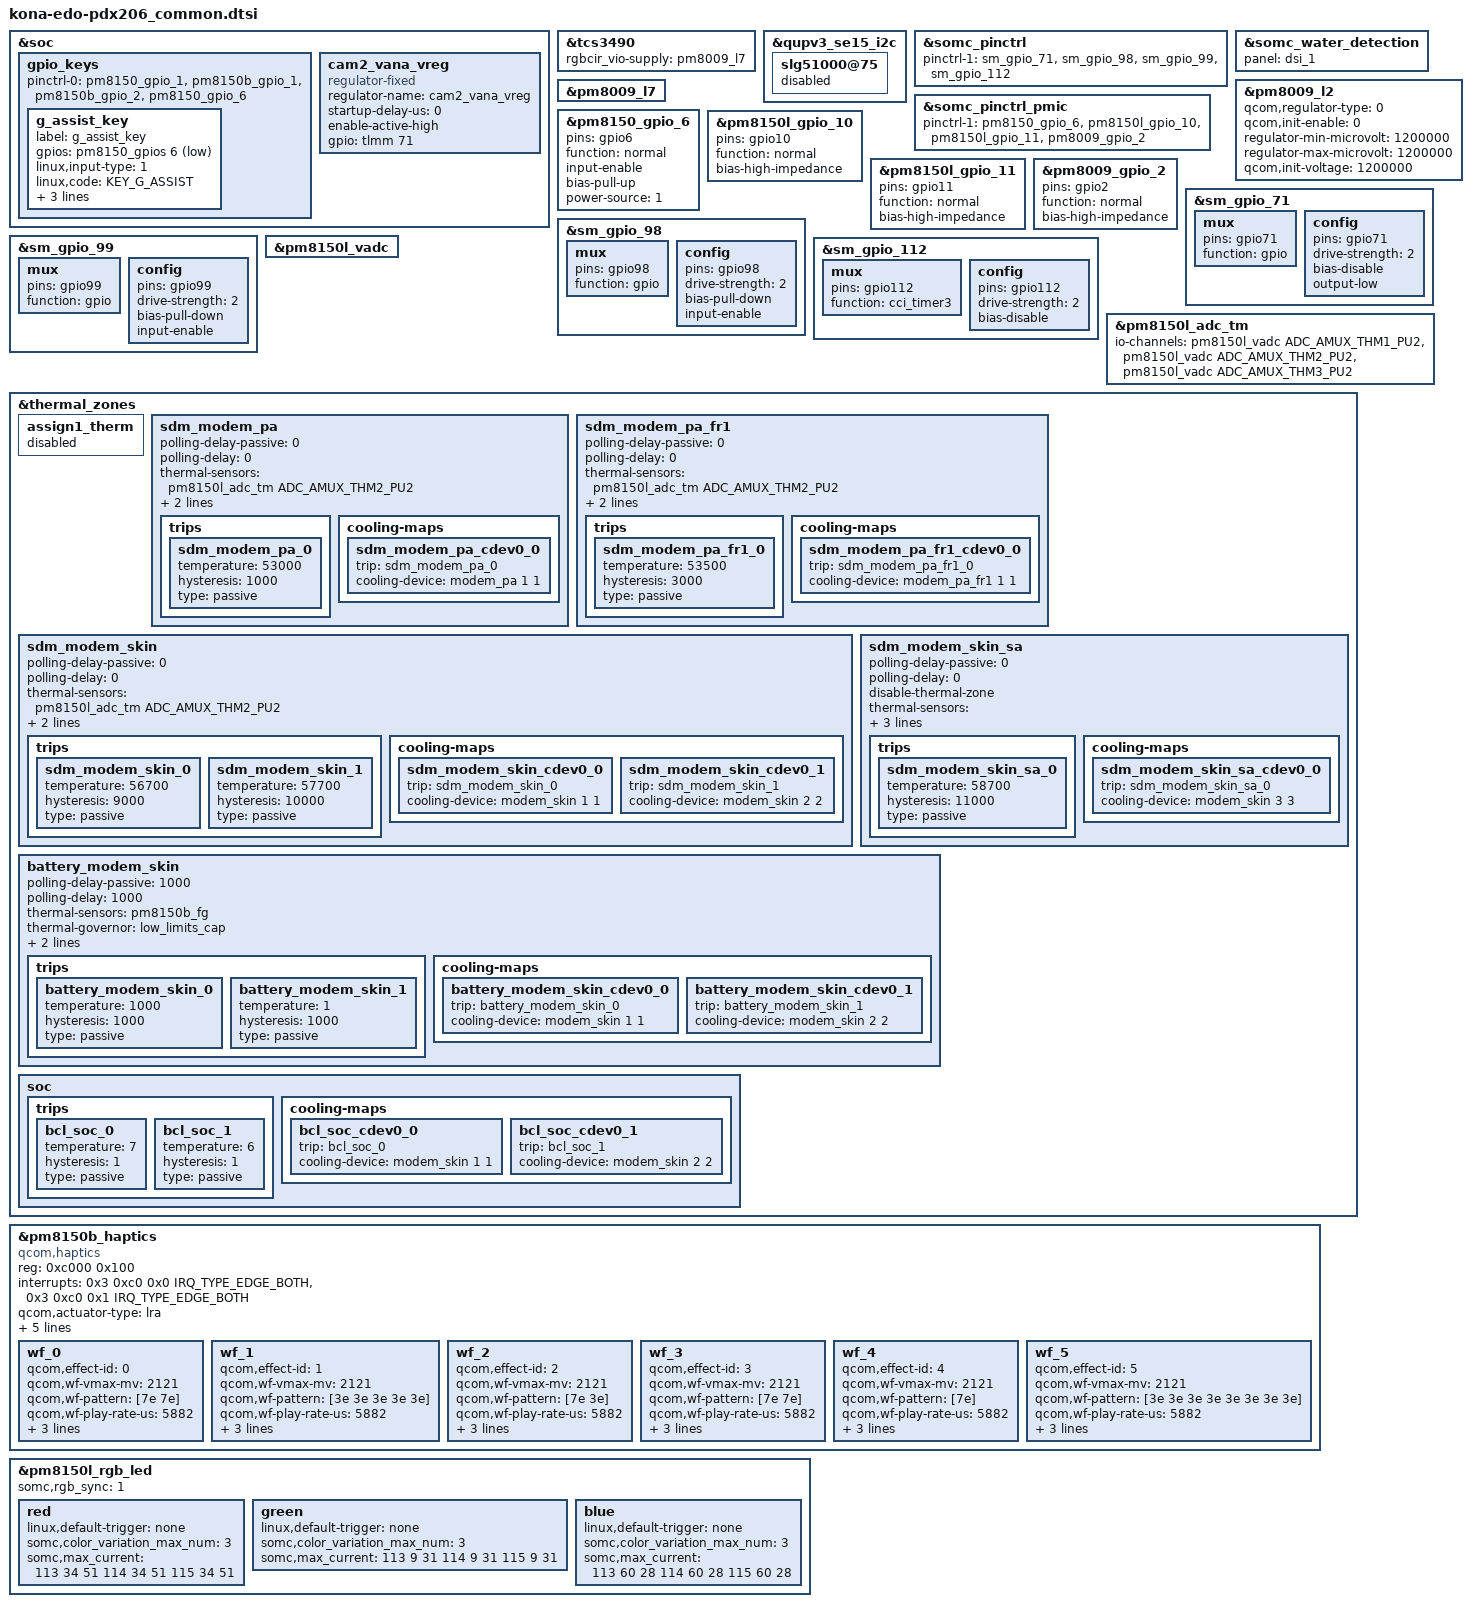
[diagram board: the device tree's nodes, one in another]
/* arch/arm64/boot/dts/vendor/somc/kona-edo-pdx206_common.dtsi
 *
 * This program is free software; you can redistribute it and/or modify
 * it under the terms of the GNU General Public License version 2 and
 * only version 2 as published by the Free Software Foundation.
 *
 * This program is distributed in the hope that it will be useful,
 * but WITHOUT ANY WARRANTY; without even the implied warranty of
 * MERCHANTABILITY or FITNESS FOR A PARTICULAR PURPOSE.  See the
 * GNU General Public License for more details.
 */

#include "kona-edo-common.dtsi"

&soc {
	gpio_keys {
		pinctrl-0 = <&pm8150_gpio_1
			     &pm8150b_gpio_1
			     &pm8150b_gpio_2
			     &pm8150_gpio_6>;
		g_assist_key {
			label = "g_assist_key";
			gpios = <&pm8150_gpios 6 GPIO_ACTIVE_LOW>;
			linux,input-type = <1>;
			linux,code = <KEY_G_ASSIST>;
			gpio-key,wakeup;
			debounce-interval = <15>;
			linux,can-disable;
		};
	};

	cam2_vana_vreg: cam2_vana_vreg {
		compatible = "regulator-fixed";
		regulator-name = "cam2_vana_vreg";
		startup-delay-us = <0>;
		enable-active-high;
		gpio = <&tlmm 71 0>;
	};
};

&tcs3490 {
	rgbcir_vio-supply = <&pm8009_l7>;
	/delete-property/ pmic_cs-supply;
};

&qupv3_se15_i2c {
	slg51000@75 {
		status = "disabled";
	};
};

&somc_pinctrl {
	/* If product common default setting is needed,
	fill pinctrl-1 value in <product>_common.dtsi */
	pinctrl-1 = <&sm_gpio_71 &sm_gpio_98 &sm_gpio_99 &sm_gpio_112>;
};

&somc_pinctrl_pmic {
	/* If product common PMIC default setting is needed,
	fill pinctrl-1 value in <product>_common.dtsi */
	pinctrl-1 = <&pm8150_gpio_6 &pm8150l_gpio_10 &pm8150l_gpio_11 &pm8009_gpio_2>;
};

&somc_water_detection {
	panel = <&dsi_1>;
};

/* Regulator config */
&pm8009_l2 {
	qcom,regulator-type = <0>;      /* LDO */
	qcom,init-enable = <0>;
	regulator-min-microvolt = <1200000>;
	regulator-max-microvolt = <1200000>;
	qcom,init-voltage = <1200000>;
	status = "okay";
};

&pm8009_l7 {
	status = "okay";
};

/* GPIO_6: G_ASSIST_N */
&pm8150_gpio_6 {
	pins = "gpio6";
	function = "normal";
	/delete-property/ bias-high-impedance;
	input-enable;
	bias-pull-up;
	power-source = <1>;
};

/* GPIO_10: NC */
&pm8150l_gpio_10 {
	pins = "gpio10";
	function = "normal";
	bias-high-impedance; /* DISABLE GPIO_10 */
};

/* GPIO_11: NC */
&pm8150l_gpio_11 {
	pins = "gpio11";
	function = "normal";
	/delete-property/ output-low;
	/delete-property/ drive-push-pull;
	/delete-property/ qcom,drive-strength;
	/delete-property/ power-source;
	bias-high-impedance; /* DISABLE GPIO_11 */
};

/* GPIO_2: NC */
&pm8009_gpio_2 {
	pins = "gpio2";
	function = "normal";
	/delete-property/ output-low;
	/delete-property/ drive-push-pull;
	/delete-property/ qcom,drive-strength;
	/delete-property/ power-source;
	bias-high-impedance; /* DISABLE GPIO_2 */
};

/* GPIO_71 : FRONTC_PWR_EN */
&sm_gpio_71 {
	mux {
		pins = "gpio71";
		function = "gpio";
	};

	config {
		pins = "gpio71";
		drive-strength = <2>;
		bias-disable;
		output-low;
	};
};

/* GPIO_98 : NC */
&sm_gpio_98 {
	mux {
		pins = "gpio98";
		function = "gpio";
	};

	config {
		pins = "gpio98";
		drive-strength = <2>;
		/delete-property/ bias-disable;
		bias-pull-down;
		input-enable;
	};
};

/* GPIO_99 : NC */
&sm_gpio_99 {
	mux {
		pins = "gpio99";
		function = "gpio";
	};

	config {
		pins = "gpio99";
		drive-strength = <2>;
		/delete-property/ bias-disable;
		bias-pull-down;
		/delete-property/ output-low;
		input-enable;
	};
};

/* GPIO_112 : XVS */
&sm_gpio_112 {
	mux {
		pins = "gpio112";
		function = "cci_timer3";
	};

	config {
		pins = "gpio112";
		drive-strength = <2>;
		/delete-property/ bias-pull-down;
		bias-disable;
		/delete-property/ input-enable;
	};
};

&pm8150l_vadc {
	/delete-node/ assign1_therm@55;
};

&pm8150l_adc_tm {
	io-channels = <&pm8150l_vadc ADC_AMUX_THM1_PU2>,
			<&pm8150l_vadc ADC_AMUX_THM2_PU2>,
			<&pm8150l_vadc ADC_AMUX_THM3_PU2>;

	/delete-node/ assign1_therm@55;
};

&thermal_zones {
	assign1_therm {
		status = "disable";
	};

	sdm_modem_pa {
		polling-delay-passive = <0>;
		polling-delay = <0>;
		thermal-sensors = <&pm8150l_adc_tm ADC_AMUX_THM2_PU2>;
		thermal-governor = "step_wise";
		wake-capable-sensor;
		trips {
			sdm_modem_pa_0: sdm_modem_pa_0 {
				temperature = <53000>;
				hysteresis = <1000>;
				type = "passive";
			};
		};
		cooling-maps {
			sdm_modem_pa_cdev0_0 {
				trip = <&sdm_modem_pa_0>;
				cooling-device = <&modem_pa 1 1>;
			};
		};
	};

	sdm_modem_pa_fr1 {
		polling-delay-passive = <0>;
		polling-delay = <0>;
		thermal-sensors = <&pm8150l_adc_tm ADC_AMUX_THM2_PU2>;
		thermal-governor = "step_wise";
		wake-capable-sensor;
		trips {
			sdm_modem_pa_fr1_0: sdm_modem_pa_fr1_0 {
				temperature = <53500>;
				hysteresis = <3000>;
				type = "passive";
			};
		};
		cooling-maps {
			sdm_modem_pa_fr1_cdev0_0 {
				trip = <&sdm_modem_pa_fr1_0>;
				cooling-device = <&modem_pa_fr1 1 1>;
			};
		};
	};

	sdm_modem_skin {
		polling-delay-passive = <0>;
		polling-delay = <0>;
		thermal-sensors = <&pm8150l_adc_tm ADC_AMUX_THM2_PU2>;
		thermal-governor = "step_wise";
		wake-capable-sensor;
		trips {
			sdm_modem_skin_0: sdm_modem_skin_0 {
				temperature = <56700>;
				hysteresis = <9000>;
				type = "passive";
			};
			sdm_modem_skin_1: sdm_modem_skin_1 {
				temperature = <57700>;
				hysteresis = <10000>;
				type = "passive";
			};
		};
		cooling-maps {
			sdm_modem_skin_cdev0_0 {
				trip = <&sdm_modem_skin_0>;
				cooling-device = <&modem_skin 1 1>;
			};
			sdm_modem_skin_cdev0_1 {
				trip = <&sdm_modem_skin_1>;
				cooling-device = <&modem_skin 2 2>;
			};
		};
	};

	sdm_modem_skin_sa {
		polling-delay-passive = <0>;
		polling-delay = <0>;
		disable-thermal-zone;
		thermal-sensors = <&pm8150l_adc_tm ADC_AMUX_THM2_PU2>;
		thermal-governor = "step_wise";
		wake-capable-sensor;
		trips {
			sdm_modem_skin_sa_0: sdm_modem_skin_sa_0 {
				temperature = <58700>;
				hysteresis = <11000>;
				type = "passive";
			};
		};
		cooling-maps {
			sdm_modem_skin_sa_cdev0_0 {
				trip = <&sdm_modem_skin_sa_0>;
				cooling-device = <&modem_skin 3 3>;
			};
		};
	};

	battery_modem_skin {
		polling-delay-passive = <1000>;
		polling-delay = <1000>;
		thermal-sensors = <&pm8150b_fg>;
		thermal-governor = "low_limits_cap";
		tracks-low;
		wake-capable-sensor;
		trips {
			battery_modem_skin_0: battery_modem_skin_0 {
				temperature = <1000>;
				hysteresis = <1000>;
				type = "passive";
			};
			battery_modem_skin_1: battery_modem_skin_1 {
				temperature = <1>;
				hysteresis = <1000>;
				type = "passive";
			};
		};
		cooling-maps {
			battery_modem_skin_cdev0_0 {
				trip = <&battery_modem_skin_0>;
				cooling-device = <&modem_skin 1 1>;
			};
			battery_modem_skin_cdev0_1 {
				trip = <&battery_modem_skin_1>;
				cooling-device = <&modem_skin 2 2>;
			};
		};
	};

	soc {
		trips {
			bcl_soc_0: bcl_soc_0 {
				temperature = <7>;
				hysteresis = <1>;
				type = "passive";
			};
			bcl_soc_1: bcl_soc_1 {
				temperature = <6>;
				hysteresis = <1>;
				type = "passive";
			};
		};
		cooling-maps {
			bcl_soc_cdev0_0 {
				trip = <&bcl_soc_0>;
				cooling-device = <&modem_skin 1 1>;
			};
			bcl_soc_cdev0_1 {
				trip = <&bcl_soc_1>;
				cooling-device = <&modem_skin 2 2>;
			};
		};
	};
};

&pm8150b_haptics {
	compatible = "qcom,haptics";
	reg = <0xc000 0x100>;
	interrupts = <0x3 0xc0 0x0 IRQ_TYPE_EDGE_BOTH>,
		     <0x3 0xc0 0x1 IRQ_TYPE_EDGE_BOTH>;
	interrupt-names = "hap-sc-irq", "hap-play-irq";
	qcom,actuator-type = "lra";
	qcom,vmax-mv = <2121>;
	qcom,play-rate-us = <5882>;
	qcom,lra-resonance-sig-shape = "sine";
	qcom,lra-auto-resonance-mode = "qwd";
	qcom,lra-allow-variable-play-rate;

	wf_0 {
		/* CLICK */
		qcom,effect-id = <0>;
		qcom,wf-vmax-mv = <2121>;
		qcom,wf-pattern = [7e 7e];
		qcom,wf-play-rate-us = <5882>;
		qcom,wf-brake-pattern = [00 00 00 00];
		qcom,wf-repeat-count = <1>;
		qcom,wf-s-repeat-count = <1>;
	};

	wf_1 {
		/* DOUBLE CLICK */
		qcom,effect-id = <1>;
		qcom,wf-vmax-mv = <2121>;
		qcom,wf-pattern = [3e 3e 3e 3e 3e];
		qcom,wf-play-rate-us = <5882>;
		qcom,wf-brake-pattern = [00 00 00 00];
		qcom,wf-repeat-count = <1>;
		qcom,wf-s-repeat-count = <1>;
	};

	wf_2 {
		/* TICK */
		qcom,effect-id = <2>;
		qcom,wf-vmax-mv = <2121>;
		qcom,wf-pattern = [7e 3e];
		qcom,wf-play-rate-us = <5882>;
		qcom,wf-brake-pattern = [00 00 00 00];
		qcom,wf-repeat-count = <1>;
		qcom,wf-s-repeat-count = <1>;
	};

	wf_3 {
		/* THUD */
		qcom,effect-id = <3>;
		qcom,wf-vmax-mv = <2121>;
		qcom,wf-pattern = [7e 7e];
		qcom,wf-play-rate-us = <5882>;
		qcom,wf-brake-pattern = [00 00 00 00];
		qcom,wf-repeat-count = <1>;
		qcom,wf-s-repeat-count = <1>;
	};

	wf_4 {
		/* POP */
		qcom,effect-id = <4>;
		qcom,wf-vmax-mv = <2121>;
		qcom,wf-pattern = [7e];
		qcom,wf-play-rate-us = <5882>;
		qcom,wf-brake-pattern = [00 00 00 00];
		qcom,wf-repeat-count = <1>;
		qcom,wf-s-repeat-count = <1>;
	};

	wf_5 {
		/* HEAVY CLICK */
		qcom,effect-id = <5>;
		qcom,wf-vmax-mv = <2121>;
		qcom,wf-pattern = [3e 3e 3e 3e 3e 3e 3e 3e];
		qcom,wf-play-rate-us = <5882>;
		qcom,wf-brake-pattern = [00 00 00 00];
		qcom,wf-repeat-count = <2>;
		qcom,wf-s-repeat-count = <1>;
	};

};

&pm8150l_rgb_led {
	somc,rgb_sync = <1>;
	red {
		linux,default-trigger = "none";
		somc,color_variation_max_num = <3>;
		somc,max_current = <
			113 34 51
			114 34 51
			115 34 51>;
	};
	green {
		linux,default-trigger = "none";
		somc,color_variation_max_num = <3>;
		somc,max_current = <
			113 9 31
			114 9 31
			115 9 31>;
	};
	blue {
		linux,default-trigger = "none";
		somc,color_variation_max_num = <3>;
		somc,max_current = <
			113 60 28
			114 60 28
			115 60 28>;
	};
};

#include "sec_touchscreen_pdx206.dtsi"
#include "usb-dp-edo-pdx206.dtsi"
#include "charger-edo-common.dtsi"
#include "charger-edo-pdx206.dtsi"
